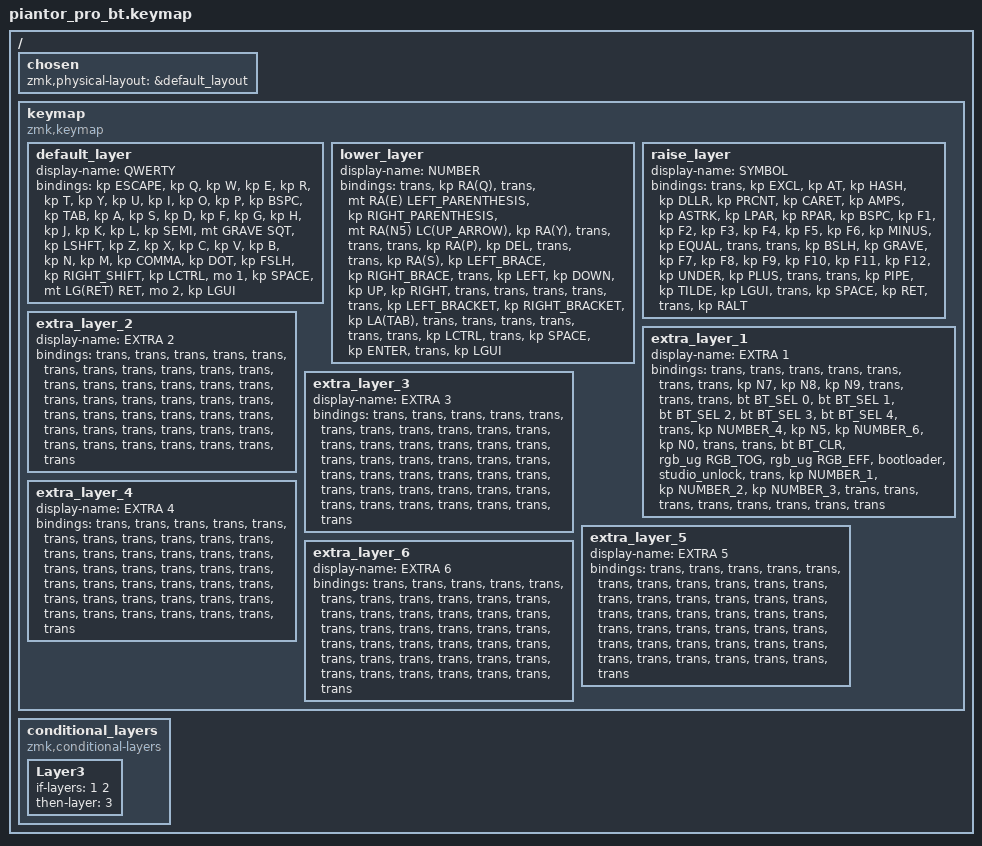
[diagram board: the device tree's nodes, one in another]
/*
 * Copyright (c) 2020 The ZMK Contributors
 *
 * SPDX-License-Identifier: MIT
 */

#include <behaviors.dtsi>
#include <dt-bindings/zmk/bt.h>
#include <dt-bindings/zmk/keys.h>
#include <dt-bindings/zmk/rgb.h>

/ {
    chosen { zmk,physical-layout = &default_layout; };
};

/ {
    keymap {
        compatible = "zmk,keymap";

        default_layer {
            display-name = "QWERTY";
            bindings = <
&kp ESCAPE  &kp Q  &kp W  &kp E  &kp R  &kp T  &kp Y  &kp U  &kp I  &kp O  &kp P  &kp BSPC  &kp TAB  &kp A  &kp S  &kp D  &kp F  &kp G  &kp H  &kp J  &kp K  &kp L  &kp SEMI  &mt GRAVE SQT  &kp LSHFT  &kp Z  &kp X  &kp C  &kp V  &kp B  &kp N  &kp M  &kp COMMA  &kp DOT  &kp FSLH  &kp RIGHT_SHIFT  &kp LCTRL  &mo 1  &kp SPACE  &mt LG(RET) RET  &mo 2  &kp LGUI
            >;
        };

        lower_layer {
            display-name = "NUMBER";
            bindings = <
&trans  &kp RA(Q)  &trans  &mt RA(E) LEFT_PARENTHESIS  &kp RIGHT_PARENTHESIS  &mt RA(N5) LC(UP_ARROW)  &kp RA(Y)  &trans  &trans  &trans  &kp RA(P)  &kp DEL  &trans  &trans  &kp RA(S)  &kp LEFT_BRACE  &kp RIGHT_BRACE  &trans  &kp LEFT  &kp DOWN  &kp UP  &kp RIGHT  &trans  &trans  &trans  &trans  &trans  &kp LEFT_BRACKET  &kp RIGHT_BRACKET  &kp LA(TAB)  &trans  &trans  &trans  &trans  &trans  &trans  &kp LCTRL  &trans  &kp SPACE  &kp ENTER  &trans  &kp LGUI
            >;
        };

        raise_layer {
            display-name = "SYMBOL";
            bindings = <
&trans  &kp EXCL  &kp AT  &kp HASH  &kp DLLR  &kp PRCNT  &kp CARET  &kp AMPS  &kp ASTRK  &kp LPAR  &kp RPAR  &kp BSPC  &kp F1  &kp F2  &kp F3  &kp F4  &kp F5  &kp F6  &kp MINUS  &kp EQUAL  &trans  &trans  &kp BSLH  &kp GRAVE  &kp F7  &kp F8  &kp F9  &kp F10  &kp F11  &kp F12  &kp UNDER  &kp PLUS  &trans  &trans  &kp PIPE  &kp TILDE  &kp LGUI  &trans  &kp SPACE  &kp RET  &trans  &kp RALT
            >;
        };

        extra_layer_1 {
            display-name = "EXTRA 1";
            bindings = <
&trans  &trans  &trans  &trans  &trans  &trans  &trans  &kp N7  &kp N8  &kp N9  &trans  &trans  &trans  &bt BT_SEL 0  &bt BT_SEL 1  &bt BT_SEL 2  &bt BT_SEL 3  &bt BT_SEL 4  &trans  &kp NUMBER_4  &kp N5  &kp NUMBER_6  &kp N0  &trans  &trans  &bt BT_CLR  &rgb_ug RGB_TOG  &rgb_ug RGB_EFF  &bootloader  &studio_unlock  &trans  &kp NUMBER_1  &kp NUMBER_2  &kp NUMBER_3  &trans  &trans  &trans  &trans  &trans  &trans  &trans  &trans
            >;
        };

        extra_layer_2 {
            display-name = "EXTRA 2";
            bindings = <
&trans  &trans  &trans  &trans  &trans  &trans  &trans  &trans  &trans  &trans  &trans  &trans  &trans  &trans  &trans  &trans  &trans  &trans  &trans  &trans  &trans  &trans  &trans  &trans  &trans  &trans  &trans  &trans  &trans  &trans  &trans  &trans  &trans  &trans  &trans  &trans  &trans  &trans  &trans  &trans  &trans  &trans
            >;
        };

        extra_layer_3 {
            display-name = "EXTRA 3";
            bindings = <
&trans  &trans  &trans  &trans  &trans  &trans  &trans  &trans  &trans  &trans  &trans  &trans  &trans  &trans  &trans  &trans  &trans  &trans  &trans  &trans  &trans  &trans  &trans  &trans  &trans  &trans  &trans  &trans  &trans  &trans  &trans  &trans  &trans  &trans  &trans  &trans  &trans  &trans  &trans  &trans  &trans  &trans
            >;
        };

        extra_layer_4 {
            display-name = "EXTRA 4";
            bindings = <
&trans  &trans  &trans  &trans  &trans  &trans  &trans  &trans  &trans  &trans  &trans  &trans  &trans  &trans  &trans  &trans  &trans  &trans  &trans  &trans  &trans  &trans  &trans  &trans  &trans  &trans  &trans  &trans  &trans  &trans  &trans  &trans  &trans  &trans  &trans  &trans  &trans  &trans  &trans  &trans  &trans  &trans
            >;
        };

        extra_layer_5 {
            display-name = "EXTRA 5";
            bindings = <
&trans  &trans  &trans  &trans  &trans  &trans  &trans  &trans  &trans  &trans  &trans  &trans  &trans  &trans  &trans  &trans  &trans  &trans  &trans  &trans  &trans  &trans  &trans  &trans  &trans  &trans  &trans  &trans  &trans  &trans  &trans  &trans  &trans  &trans  &trans  &trans  &trans  &trans  &trans  &trans  &trans  &trans
            >;
        };

        extra_layer_6 {
            display-name = "EXTRA 6";
            bindings = <
&trans  &trans  &trans  &trans  &trans  &trans  &trans  &trans  &trans  &trans  &trans  &trans  &trans  &trans  &trans  &trans  &trans  &trans  &trans  &trans  &trans  &trans  &trans  &trans  &trans  &trans  &trans  &trans  &trans  &trans  &trans  &trans  &trans  &trans  &trans  &trans  &trans  &trans  &trans  &trans  &trans  &trans
            >;
        };
    };

    conditional_layers {
        compatible = "zmk,conditional-layers";

        Layer3 {
            if-layers = <1 2>;
            then-layer = <3>;
        };
    };
};
